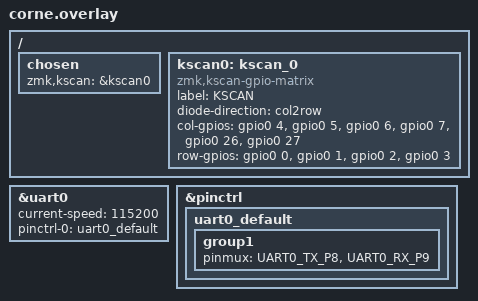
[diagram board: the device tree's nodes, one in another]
/ {
    /* Wir löschen die Suche nach dem Pro-Micro I2C, die den Fehler verursacht */
    /delete-node/ &pro_micro_i2c;

    chosen {
        zmk,kscan = &kscan0;
        /* Wir deaktivieren den Standard-Transform, da wir direkt mappen */
        /delete-property/ zmk,matrix-transform;
    };

    kscan0: kscan_0 {
        compatible = "zmk,kscan-gpio-matrix";
        label = "KSCAN";
        diode-direction = "col2row";

        col-gpios
            = <&gpio0 4 GPIO_ACTIVE_HIGH>  // GP4
            , <&gpio0 5 GPIO_ACTIVE_HIGH>  // GP5
            , <&gpio0 6 GPIO_ACTIVE_HIGH>  // GP6
            , <&gpio0 7 GPIO_ACTIVE_HIGH>  // GP7
            , <&gpio0 26 GPIO_ACTIVE_HIGH> // GP26
            , <&gpio0 27 GPIO_ACTIVE_HIGH>;// GP27

        row-gpios
            = <&gpio0 0 (GPIO_ACTIVE_HIGH | GPIO_PULL_DOWN)> // GP0
            , <&gpio0 1 (GPIO_ACTIVE_HIGH | GPIO_PULL_DOWN)> // GP1
            , <&gpio0 2 (GPIO_ACTIVE_HIGH | GPIO_PULL_DOWN)> // GP2
            , <&gpio0 3 (GPIO_ACTIVE_HIGH | GPIO_PULL_DOWN)>; // GP3
    };
};

/* UART für Split-Kommunikation neu definieren ohne Pro-Micro-Labels */
&uart0 {
    status = "okay";
    current-speed = <115200>;
    /delete-property/ pinctrl-0;
    /delete-property/ pinctrl-names;
    pinctrl-0 = <&uart0_default>;
    pinctrl-names = "default";
};

&pinctrl {
    uart0_default: uart0_default {
        group1 {
            pinmux = <UART0_TX_P8>, <UART0_RX_P9>;
        };
    };
};
